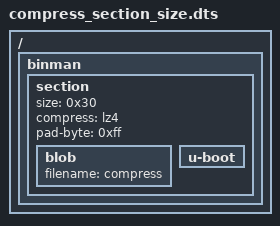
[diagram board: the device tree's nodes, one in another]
// SPDX-License-Identifier: GPL-2.0+
/dts-v1/;

/ {
	binman {
		section {
			size = <0x30>;
			compress = "lz4";
			pad-byte = <0xff>;
			blob {
				filename = "compress";
			};

			u-boot {
			};
		};
	};
};
